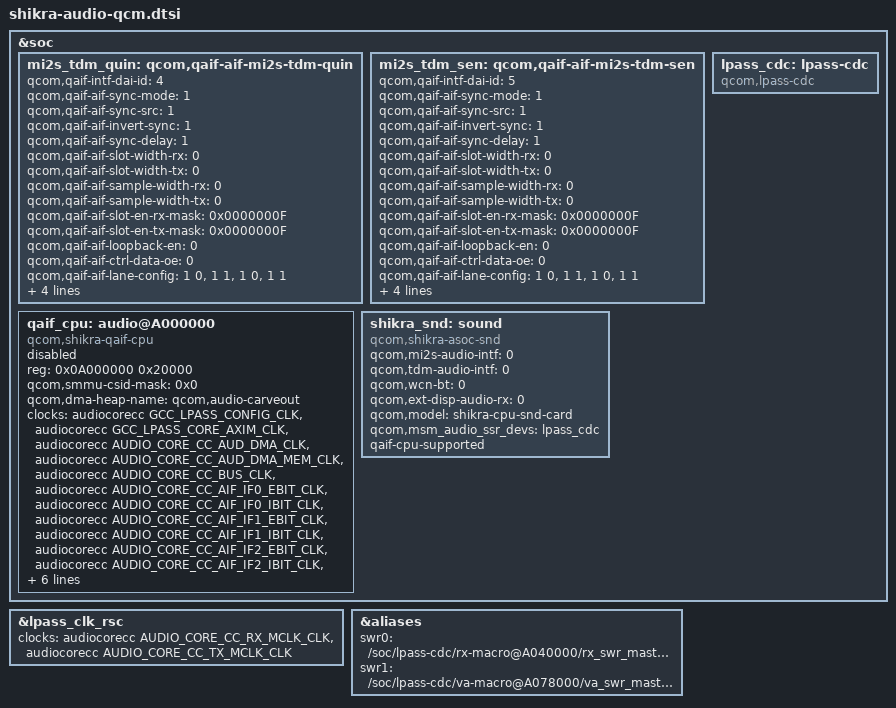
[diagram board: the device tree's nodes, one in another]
/*
 * Copyright (c) Qualcomm Technologies, Inc. and/or its subsidiaries.
 * SPDX-License-Identifier: BSD-3-Clause
*/

#include <bindings/qcom,audio-ext-clk.h>
#include <dt-bindings/clock/qcom,shikra-audiocorecc.h>

&soc {

	mi2s_tdm_quin: qcom,qaif-aif-mi2s-tdm-quin {
		qcom,qaif-intf-dai-id = <4>;
		qcom,qaif-aif-sync-mode = <1>;
		qcom,qaif-aif-sync-src = <1>;
		qcom,qaif-aif-invert-sync = <1>;
		qcom,qaif-aif-sync-delay = <1>;
		qcom,qaif-aif-slot-width-rx = <0>;    /* MIC/RX Path */
		qcom,qaif-aif-slot-width-tx = <0>;    /* SPKR/TX Path */
		qcom,qaif-aif-sample-width-rx = <0>;    /* MIC/RX Path */
		qcom,qaif-aif-sample-width-tx = <0>;    /* SPKR/TX Path */
		qcom,qaif-aif-slot-en-rx-mask = <0x0000000F>;    /* MIC/RX Path */
		qcom,qaif-aif-slot-en-tx-mask = <0x0000000F>;    /* SPKR/TX Path */
		qcom,qaif-aif-loopback-en = <0>;
		qcom,qaif-aif-ctrl-data-oe = <0>;
		qcom,qaif-aif-lane-config = <1 0>,  /* Lane 0: Enabled, TX_SPKR */
						<1 1>,  /* Lane 1: Enabled, RX_MIC */
						<1 0>,  /* Lane 2: Enabled, TX_SPKR */
						<1 1>;  /* Lane 3: Enabled, RX_MIC */
						/* Lanes 4-7 disabled by default */
		qcom,qaif-aif-mono-mode-tx = <0>;  /* MIC/RX Path, 0=STEREO, 1=MONO */
		qcom,qaif-aif-mono-mode-rx = <0>;  /* SPKR/TX Path, 0=STEREO, 1=MONO */

		qcom,qaif-aif-full-cycle-en = <0>;  /* effective if SYNC MASTER Mode (SYNC_SRC=1) */
		qcom,qaif-aif-bits-per-lane = <0>;  /* FRAME_CFG */
	};

	mi2s_tdm_sen: qcom,qaif-aif-mi2s-tdm-sen {
		qcom,qaif-intf-dai-id = <5>;
		qcom,qaif-aif-sync-mode = <1>;
		qcom,qaif-aif-sync-src = <1>;
		qcom,qaif-aif-invert-sync = <1>;
		qcom,qaif-aif-sync-delay = <1>;
		qcom,qaif-aif-slot-width-rx = <0>;    /* MIC/RX Path */
		qcom,qaif-aif-slot-width-tx = <0>;    /* SPKR/TX Path */
		qcom,qaif-aif-sample-width-rx = <0>;    /* MIC/RX Path */
		qcom,qaif-aif-sample-width-tx = <0>;    /* SPKR/TX Path */
		qcom,qaif-aif-slot-en-rx-mask = <0x0000000F>;    /* MIC/RX Path */
		qcom,qaif-aif-slot-en-tx-mask = <0x0000000F>;    /* SPKR/TX Path */
		qcom,qaif-aif-loopback-en = <0>;
		qcom,qaif-aif-ctrl-data-oe = <0>;
		qcom,qaif-aif-lane-config = <1 0>,  /* Lane 0: Enabled, TX_SPKR */
						<1 1>,  /* Lane 1: Enabled, RX_MIC */
						<1 0>,  /* Lane 2: Enabled, TX_SPKR */
						<1 1>;  /* Lane 3: Enabled, RX_MIC */
						/* Lanes 4-7 disabled by default */
		qcom,qaif-aif-mono-mode-tx = <0>;  /* MIC/RX Path, 0=STEREO, 1=MONO */
		qcom,qaif-aif-mono-mode-rx = <0>;  /* SPKR/TX Path, 0=STEREO, 1=MONO */

		qcom,qaif-aif-full-cycle-en = <0>;  /* effective if SYNC MASTER Mode (SYNC_SRC=1) */
		qcom,qaif-aif-bits-per-lane = <0>;  /* FRAME_CFG */
	};

	qaif_cpu: audio@A000000 {
		compatible = "qcom,shikra-qaif-cpu";
		reg = <0x0A000000 0x20000>;
		reg-names = "audio-qaif-core";
		qcom,smmu-csid-mask = <0x0>;
		qcom,dma-heap-name = "qcom,audio-carveout";
		clocks = <&audiocorecc GCC_LPASS_CONFIG_CLK>,
			<&audiocorecc GCC_LPASS_CORE_AXIM_CLK>,
			<&audiocorecc AUDIO_CORE_CC_AUD_DMA_CLK>,
			<&audiocorecc AUDIO_CORE_CC_AUD_DMA_MEM_CLK>,
			<&audiocorecc AUDIO_CORE_CC_BUS_CLK>,
			<&audiocorecc AUDIO_CORE_CC_AIF_IF0_EBIT_CLK>,
			<&audiocorecc AUDIO_CORE_CC_AIF_IF0_IBIT_CLK>,
			<&audiocorecc AUDIO_CORE_CC_AIF_IF1_EBIT_CLK>,
			<&audiocorecc AUDIO_CORE_CC_AIF_IF1_IBIT_CLK>,
			<&audiocorecc AUDIO_CORE_CC_AIF_IF2_EBIT_CLK>,
			<&audiocorecc AUDIO_CORE_CC_AIF_IF2_IBIT_CLK>,
			<&audiocorecc AUDIO_CORE_CC_AIF_IF3_EBIT_CLK>,
			<&audiocorecc AUDIO_CORE_CC_AIF_IF3_IBIT_CLK>,
			<&audiocorecc AUDIO_CORE_CC_EXT_MCLKA_OUT_CLK>,
			<&audiocorecc AUDIO_CORE_CC_EXT_MCLKB_OUT_CLK>;
		clock-names = "gcc_lpass_config_clk",
			"gcc_lpass_core_axim_clk",
			"audio_core_cc_aud_dma_clk",
			"audio_core_cc_aud_dma_mem_clk",
			"audio_core_cc_bus_clk",
			"audio_core_cc_aif_if0_ebit_clk",
			"audio_core_cc_aif_if0_ibit_clk",
			"audio_core_cc_aif_if1_ebit_clk",
			"audio_core_cc_aif_if1_ibit_clk",
			"audio_core_cc_aif_if2_ebit_clk",
			"audio_core_cc_aif_if2_ibit_clk",
			"audio_core_cc_aif_if3_ebit_clk",
			"audio_core_cc_aif_if3_ibit_clk",
			"audio_core_cc_ext_mclka_clk",
			"audio_core_cc_ext_mclkb_clk";
		#sound-dai-cells = <1>;
		#address-cells = <1>;
		#size-cells = <0>;
		interrupts = <GIC_SPI 331 IRQ_TYPE_LEVEL_HIGH>;
		interrupt-names = "qaif-irq-audio-core";
		aif-interface = <&mi2s_tdm_quin>, <&mi2s_tdm_sen>;
		status = "disabled";
	};

	lpass_cdc: lpass-cdc {
		compatible = "qcom,lpass-cdc";
	};

	shikra_snd: sound {
		compatible = "qcom,shikra-asoc-snd";
		qcom,mi2s-audio-intf = <0>;
		qcom,tdm-audio-intf = <0>;
		qcom,wcn-bt = <0>;
		qcom,ext-disp-audio-rx = <0>;
	};
};

#include "shikra-audio-overlay.dtsi"

&shikra_snd{
	qcom,model = "shikra-cpu-snd-card";
	qcom,msm_audio_ssr_devs = <&lpass_cdc>;
	qaif-cpu-supported;
};

&lpass_clk_rsc {
	clocks = <&audiocorecc AUDIO_CORE_CC_RX_MCLK_CLK>,
				<&audiocorecc AUDIO_CORE_CC_TX_MCLK_CLK>;
};

&aliases {
	swr0 = "/soc/lpass-cdc/rx-macro@A040000/rx_swr_master";
	swr1 = "/soc/lpass-cdc/va-macro@A078000/va_swr_master";
};
